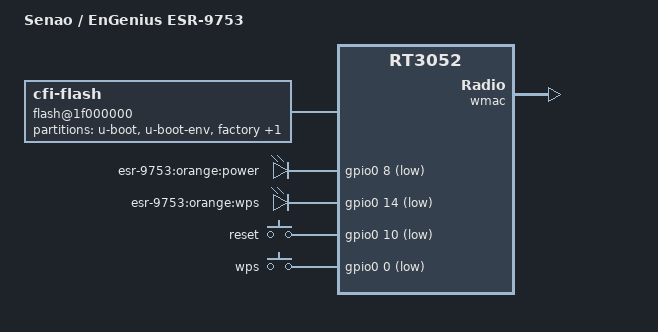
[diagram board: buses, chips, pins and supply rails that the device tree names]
/dts-v1/;

#include "rt3050.dtsi"

#include <dt-bindings/gpio/gpio.h>
#include <dt-bindings/input/input.h>

/ {
	compatible = "engenius,esr-9753", "ralink,rt3052-soc";
	model = "Senao / EnGenius ESR-9753";

	aliases {
		led-boot = &led_power;
		led-failsafe = &led_power;
		led-running = &led_power;
		led-upgrade = &led_power;
	};

	flash@1f000000 {
		compatible = "cfi-flash";
		reg = <0x1f000000 0x800000>;
		bank-width = <2>;
		device-width = <2>;

		partitions {
			compatible = "fixed-partitions";
			#address-cells = <1>;
			#size-cells = <1>;

			partition@0 {
				label = "u-boot";
				reg = <0x0 0x30000>;
				read-only;
			};

			partition@30000 {
				label = "u-boot-env";
				reg = <0x30000 0x10000>;
				read-only;
			};

			factory: partition@40000 {
				label = "factory";
				reg = <0x40000 0x10000>;
				read-only;
			};

			partition@50000 {
				compatible = "denx,uimage";
				label = "firmware";
				reg = <0x50000 0x3b0000>;
			};
		};
	};

	leds {
		compatible = "gpio-leds";

		led_power: power {
			label = "esr-9753:orange:power";
			gpios = <&gpio0 8 GPIO_ACTIVE_LOW>;
		};

		wps {
			label = "esr-9753:orange:wps";
			gpios = <&gpio0 14 GPIO_ACTIVE_LOW>;
		};
	};

	keys {
		compatible = "gpio-keys-polled";
		poll-interval = <20>;

		reset {
			label = "reset";
			gpios = <&gpio0 10 GPIO_ACTIVE_LOW>;
			linux,code = <KEY_RESTART>;
		};

		wps {
			label = "wps";
			gpios = <&gpio0 0 GPIO_ACTIVE_LOW>;
			linux,code = <KEY_WPS_BUTTON>;
		};
	};
};

&state_default {
	gpio {
		groups = "spi", "i2c", "jtag", "rgmii", "mdio", "uartf";
		function = "gpio";
	};
};

&ethernet {
	mtd-mac-address = <&factory 0x4>;
};

&esw {
	mediatek,portmap = <0x3e>;
};

&wmac {
	ralink,mtd-eeprom = <&factory 0x0>;
};
